# STM32G081xx register map
File version: 1.0
Registers are 32-bit, read-write, reset 0x0 unless marked. A register's access mark holds for its fields unless they carry their own. Offsets are from the block's base; lines under a group give offsets from that group; [hi:lo] are bit positions; {n}, {i} and the like mark numbered series; 'fields as' and 'values as' point back to an identical list; <NAME> marks a mode.

## Memory map
0x40000000 TIM2 — TIM
0x40000400 TIM3 — TIM
0x40001000 TIM6 — TIM
0x40001400 TIM7 — TIM
0x40002000 TIM14 — TIM
0x40002800 RTC — Real-Time Clock
0x40002C00 WWDG — Window WATCHDOG
0x40003000 IWDG — Independent WATCHDOG
0x40003800 SPI2 — Serial Peripheral Interface
0x40004400 USART2 — Universal Synchronous Asynchronous Receiver Transmitter
0x40004800 USART3 — Universal Synchronous Asynchronous Receiver Transmitter
0x40004C00 USART4 — Universal Synchronous Asynchronous Receiver Transmitter
0x40005400 I2C1 — Inter-integrated Circuit Interface
0x40005800 I2C2 — Inter-integrated Circuit Interface
0x40007000 PWR — Power Control
0x40007400 DAC — Digital to Analog Converter
0x40007400 DAC1 — Digital to Analog Converter
0x40007800 CEC — HDMI-CEC
0x40007C00 LPTIM1 — LPTIMER
0x40008000 LPUART1 — Universal Synchronous Asynchronous Receiver Transmitter
0x40009400 LPTIM2 — LPTIMER
0x4000A000 UCPD1 — UCPD
0x4000A400 UCPD2 — UCPD
0x4000B000 TAMP — Tamper and backup registers
0x40010000 SYSCFG — System configuration controller
0x40010030 VREFBUF
0x40010200 COMP1 — Comparator
0x40010200 COMP12_COMMON
0x40010204 COMP2 — Comparator
0x40012400 ADC1 — Analog to Digital Converter
0x40012C00 TIM1 — TIM
0x40013000 SPI1 — Serial Peripheral Interface
0x40013800 USART1 — Universal Synchronous Asynchronous Receiver Transmitter
0x40014000 TIM15 — TIM
0x40014400 TIM16 — TIM
0x40014800 TIM17 — TIM
0x40015800 DBG — Debug MCU
0x40020000 DMA1
0x40020800 DMAMUX1 — DMA Multiplexer
0x40021000 RCC — Reset and Clock Control
0x40021800 EXTI — Asynch Interrupt/Event Controller (EXTI)
0x40022000 FLASH — FLASH Registers
0x40023000 CRC — CRC calculation unit
0x40025000 RNG
0x40026000 AES — AES hardware accelerator
0x40026000 AES1 — AES hardware accelerator
0x50000000 GPIOA — General Purpose I/O
0x50000400 GPIOB — General Purpose I/O
0x50000800 GPIOC — General Purpose I/O
0x50000C00 GPIOD — General Purpose I/O
0x50001400 GPIOF — General Purpose I/O

## Interrupts
0 WWDG — Window WatchDog Interrupt
2 RTC_TAMP (RTC, TAMP) — RTC interrupt through the EXTI line 19 & 21
3 FLASH — FLASH global Interrupt
4 RCC — RCC global Interrupt
5 EXTI0_1 (EXTI) — EXTI 0 and 1 Interrupts
6 EXTI2_3 (EXTI) — EXTI Line 2 and 3 Interrupts
7 EXTI4_15 (EXTI) — EXTI Line 4 to 15 Interrupts
8 UCPD1_2 (UCPD1) — UCPD1 and UCPD2 global Interrupt
9 DMA1_Channel1 (DMA1) — DMA1 Channel 1 Interrupt
10 DMA1_Channel2_3 (DMA1) — DMA1 Channel 2 and Channel 3 Interrupts
11 DMA1_Ch4_7_DMAMUX1_OVR (DMA1, DMAMUX1) — DMA1 Channel 4 to Channel 7 and DMAMUX1 Overrun Interrupts
12 ADC1_COMP (ADC1) — ADC1, COMP1 and COMP2 Interrupts (combined with EXTI 17 & 18)
13 TIM1_BRK_UP_TRG_COM (TIM1) — TIM1 Break, Update, Trigger and Commutation Interrupts
14 TIM1_CC (TIM1) — TIM1 Capture Compare Interrupt
15 TIM2 — TIM2 Interrupt
16 TIM3 — TIM3 global Interrupt
17 TIM6_DAC_LPTIM1 (TIM6, DAC, LPTIM1) — TIM6, DAC and LPTIM1 global Interrupts
18 TIM7_LPTIM2 (TIM7, LPTIM2) — TIM7 and LPTIM2 global Interrupt
19 TIM14 — TIM14 global Interrupt
20 TIM15 — TIM15 global Interrupt
21 TIM16 — TIM16 global Interrupt
22 TIM17 — TIM17 global Interrupt
23 I2C1 — I2C1 Interrupt (combined with EXTI 23)
24 I2C2 — I2C2 Interrupt
25 SPI1 — SPI1/I2S1 Interrupt
26 SPI2 — SPI2 Interrupt
27 USART1 — USART1 Interrupt
28 USART2 — USART2 Interrupt
29 USART3_4_LPUART1 (USART3, LPUART1) — USART3, USART4 and LPUART1 globlal Interrupts (combined with EXTI 28)
30 CEC — CEC Interrupt(combined with EXTI 27)
31 AES_RNG (RNG, AES) — AES & RNG Interrupt

## TIM6 — TIM
Base 0x40001000
Same registers: TIM7 0x40001400
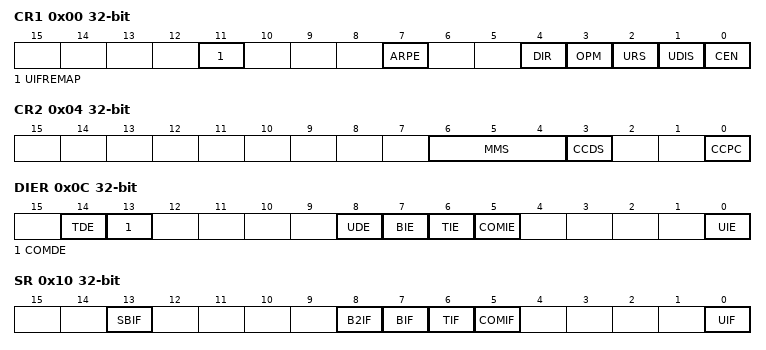
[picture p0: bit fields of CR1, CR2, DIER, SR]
0x00 CR1 — TIM control register 1
  [11] UIFREMAP — Update interrupt flag remap
  [7] ARPE — Auto-reload preload enable
  [4] DIR — Direction
    0=UP (Timer counter counts up); 1=DOWN (Timer counter counts down)
  [3] OPM — One pulse mode
    1=SINGLE (Counter stops counting at the next update event); 0=REPETITIVE (Counter is not stopped at update event)
  [2] URS — Update request source
    0=REGULAR (Counter overflow/underflow, Setting the UG bit or Update generation through the slave mode controller generates an update request); 1=COUNTER (Only counter overflow/underflow generates an update request)
  [1] UDIS — Update disable
  [0] CEN — Counter enable
0x04 CR2 — TIM control register 2
  [6:4] MMS — MMS[2:0] bits (Master Mode Selection)
    0=RESET (UG bit from the TIMx_EGR register is used as trigger output); 1=ENABLE (Counter Enable signal (CNT_EN) is used as trigger output); 2=UPDATE (Update event is used as trigger output); 3=CC1IF (CC1 capture or a compare match is used as trigger output); {v}=OC{v-3}REF (OC{v-3}REF signal is used as trigger output) (v=4..7)
  [3] CCDS — Capture/Compare DMA Selection
    0=CC (CCx DMA request sent when CCx event occurs); 1=UPDATE (CCx DMA requests sent when update event occurs)
  [0] CCPC — Capture/Compare Preloaded Control
0x08 SMCR — TIM slave mode control register
  [3] OCCS — OCREF clear selection
0x0C DIER — TIM DMA/interrupt enable register
  [14] TDE — Trigger DMA request enable
  [13] COMDE — COM DMA request enable
  [8] UDE — Update DMA request enable
  [7] BIE — Break interrupt enable
  [6] TIE — Trigger interrupt enable
  [5] COMIE — COM interrupt enable
  [0] UIE — Update interrupt enable
0x10 SR — TIM status register
  [13] SBIF — System Break interrupt Flag
  [8] B2IF — Break 2 interrupt Flag
  [7] BIF — Break interrupt Flag
  [6] TIF — Trigger interrupt Flag
  [5] COMIF — COM interrupt Flag
  [0] UIF — Update interrupt Flag
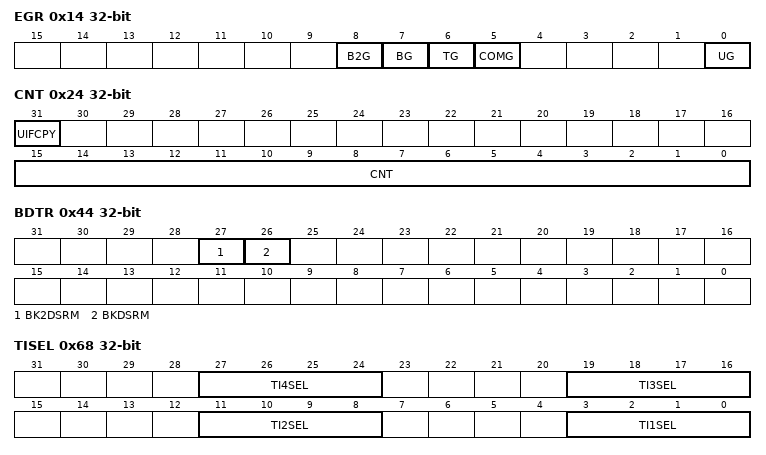
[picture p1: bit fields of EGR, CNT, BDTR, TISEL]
0x14 EGR — TIM event generation register
  [8] B2G — Break 2 Generation
  [7] BG — Break Generation
  [6] TG — Trigger Generation
  [5] COMG — Capture/Compare Control Update Generation
  [0] UG — Update Generation
0x24 CNT — TIM counter register
  [31] UIFCPY — Update interrupt flag copy (if UIFREMAP=1)
  [15:0] CNT — Counter Value
0x28 PSC — TIM prescaler register
  [15:0] PSC — Prescaler Value
0x2C ARR — TIM auto-reload register
  [15:0] ARR — Actual auto-reload Value
0x44 BDTR — TIM break and dead-time register
  [27] BK2DSRM — Break2 disarming/re-arming
  [26] BKDSRM — Break disarming/re-arming
0x4C DMAR — TIM DMA address for full transfer
  [15:0] DMAB — DMA register for burst accesses
0x50 OR1 — TIM option register
0x60 AF1 — TIM alternate function register 1
0x64 AF2 — TIM alternate function register 2
0x68 TISEL — TIM Input Selection register
  [8n-5:8n-8] TI{n}SEL (n=1..4) — TI{n}SEL[3:0] bits (TIM TI{n} SEL)
